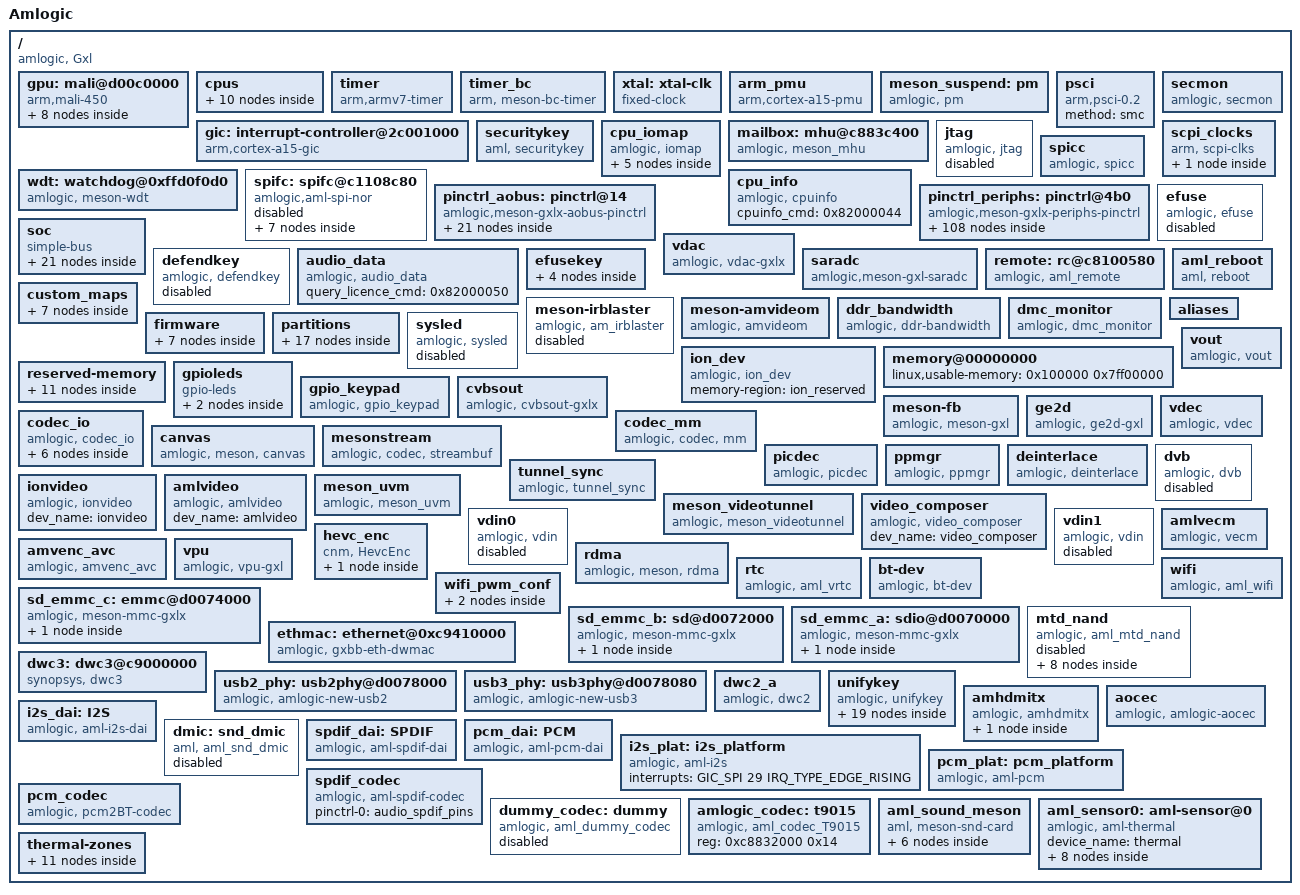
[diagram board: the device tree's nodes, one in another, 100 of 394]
/dts-v1/;

/* dt-bindings from khadas/linux khadas-vims-4.9.y (bd9460728746cc080acbaa084e53460437f43211), include/ */
#include <dt-bindings/clock/amlogic,gxl-clkc.h>
#include <dt-bindings/gpio/gpio.h>
#include <dt-bindings/interrupt-controller/arm-gic.h>
#include <dt-bindings/interrupt-controller/irq.h>
#include <dt-bindings/input/linux-event-codes.h>
#include <dt-bindings/thermal/thermal.h>

/ {
	model = "Amlogic";
	amlogic-dt-id = "gxlx2_p291_2g";
	compatible = "amlogic, Gxl";
	interrupt-parent = <&gic>;
	#address-cells = <1>;
	#size-cells = <1>;

	gpu: mali@d00c0000 {
		#cooling-cells = <2>;
		compatible = "arm,mali-450";
		interrupt-parent = <&gic>;
		reg = <0xd00c0000 0x40000 0xc1104440 0x1000 0xc8100000 0x1000 0xc883c000 0x1000 0xc1104440 0x1000>;
		interrupts = <GIC_SPI 160 IRQ_TYPE_LEVEL_HIGH>,
		             <GIC_SPI 161 IRQ_TYPE_LEVEL_HIGH>,
		             <GIC_SPI 162 IRQ_TYPE_LEVEL_HIGH>,
		             <GIC_SPI 163 IRQ_TYPE_LEVEL_HIGH>,
		             <GIC_SPI 164 IRQ_TYPE_LEVEL_HIGH>,
		             <GIC_SPI 165 IRQ_TYPE_LEVEL_HIGH>,
		             <GIC_SPI 166 IRQ_TYPE_LEVEL_HIGH>,
		             <GIC_SPI 167 IRQ_TYPE_LEVEL_HIGH>;
		interrupt-names = "IRQGP", "IRQGPMMU", "IRQPP", "IRQPMU", "IRQPP0", "IRQPPMMU0", "IRQPP1", "IRQPPMMU1";
		pmu_domain_config = <0x01 0x02 0x04 0x00 0x00 0x00 0x00 0x00 0x00 0x01 0x02 0x00>;
		pmu_switch_delay = <0xffff>;
		num_of_pp = <2>;
		def_clock = <0x03>;
		sc_mpp = <0x02>;
		tbl = <0x02 0x03 0x04 0x05 0x06 0x07>;
		clocks = <&clkc CLKID_GPU_MUX>, <&clkc CLKID_GP0_PLL>;
		clock-names = "gpu_mux", "gp0_pll";
		control_interval = <200>;
		phandle = <0x85>;

		clk125_cfg: clk125_cfg {
			clk_freq = <125000000>;
			clk_parent = "fclk_div4";
			clkp_freq = <500000000>;
			voltage = <1150>;
			keep_count = <5>;
			threshold = <30 120>;
			phandle = <0x02>;
		};

		clk250_cfg: clk250_cfg {
			clk_freq = <250000000>;
			clk_parent = "fclk_div4";
			clkp_freq = <500000000>;
			voltage = <1150>;
			keep_count = <5>;
			threshold = <80 170>;
			phandle = <0x87>;
		};

		clk285_cfg: clk285_cfg {
			clk_freq = <285000000>;
			clk_parent = "fclk_div7";
			clkp_freq = <285000000>;
			voltage = <1150>;
			keep_count = <5>;
			threshold = <100 190>;
			phandle = <0x03>;
		};

		clk400_cfg: clk400_cfg {
			clk_freq = <400000000>;
			clk_parent = "fclk_div5";
			clkp_freq = <400000000>;
			voltage = <1150>;
			keep_count = <5>;
			threshold = <152 207>;
			phandle = <0x04>;
		};

		clk500_cfg: clk500_cfg {
			clk_freq = <500000000>;
			clk_parent = "fclk_div4";
			clkp_freq = <500000000>;
			voltage = <1150>;
			keep_count = <5>;
			threshold = <180 220>;
			phandle = <0x05>;
		};

		clk666_cfg: clk666_cfg {
			clk_freq = <666000000>;
			clk_parent = "fclk_div3";
			clkp_freq = <666000000>;
			voltage = <1150>;
			keep_count = <5>;
			threshold = <210 236>;
			phandle = <0x06>;
		};

		clk750_cfg: clk750_cfg {
			clk_freq = <744000000>;
			clk_parent = "gp0_pll";
			clkp_freq = <744000000>;
			voltage = <1150>;
			keep_count = <5>;
			threshold = <230 255>;
			phandle = <0x07>;
		};

		clk800_cfg: clk800_cfg {
			clk_freq = <792000000>;
			clk_parent = "gp0_pll";
			clkp_freq = <792000000>;
			voltage = <1150>;
			keep_count = <5>;
			threshold = <230 255>;
			phandle = <0x88>;
		};
	};

	cpus: cpus {
		#address-cells = <1>;
		#size-cells = <0>;
		phandle = <0x89>;

		cpu-map {

			cluster0: cluster0 {
				phandle = <0x8a>;

				core0 {
					cpu = <&CPU0>;
				};

				core1 {
					cpu = <&CPU1>;
				};

				core2 {
					cpu = <&CPU2>;
				};

				core3 {
					cpu = <&CPU3>;
				};
			};
		};

		CPU0: cpu@0 {
			device_type = "cpu";
			compatible = "arm,cortex-a53", "arm,armv8";
			reg = <0x00>;
			enable-method = "psci";
			clocks = <&scpi_dvfs 0>;
			clock-names = "cpu-cluster.0";
			phandle = <0x09>;
		};

		CPU1: cpu@1 {
			device_type = "cpu";
			compatible = "arm,cortex-a53", "arm,armv8";
			reg = <0x01>;
			enable-method = "psci";
			clocks = <&scpi_dvfs 0>;
			clock-names = "cpu-cluster.0";
			phandle = <0x0a>;
		};

		CPU2: cpu@2 {
			device_type = "cpu";
			compatible = "arm,cortex-a53", "arm,armv8";
			reg = <0x02>;
			enable-method = "psci";
			clocks = <&scpi_dvfs 0>;
			clock-names = "cpu-cluster.0";
			phandle = <0x0b>;
		};

		CPU3: cpu@3 {
			device_type = "cpu";
			compatible = "arm,cortex-a53", "arm,armv8";
			reg = <0x03>;
			enable-method = "psci";
			clocks = <&scpi_dvfs 0>;
			clock-names = "cpu-cluster.0";
			phandle = <0x0c>;
		};
	};

	timer {
		compatible = "arm,armv7-timer";
		interrupts = <GIC_PPI 13 (GIC_CPU_MASK_SIMPLE(8) | IRQ_TYPE_EDGE_RISING)>,
		             <GIC_PPI 14 (GIC_CPU_MASK_SIMPLE(8) | IRQ_TYPE_EDGE_RISING)>,
		             <GIC_PPI 11 (GIC_CPU_MASK_SIMPLE(8) | IRQ_TYPE_EDGE_RISING)>,
		             <GIC_PPI 10 (GIC_CPU_MASK_SIMPLE(8) | IRQ_TYPE_EDGE_RISING)>;
	};

	timer_bc {
		compatible = "arm, meson-bc-timer";
		reg = <0xc1109990 0x04 0xc1109994 0x04>;
		timer_name = "Meson TimerF";
		clockevent-rating = <300>;
		clockevent-shift = <20>;
		clockevent-features = <0x23>;
		interrupts = <GIC_SPI 60 IRQ_TYPE_EDGE_RISING>;
		bit_enable = <0x10>;
		bit_mode = <0x0c>;
		bit_resolution = <0>;
	};

	xtal: xtal-clk {
		compatible = "fixed-clock";
		clock-frequency = <24000000>;
		clock-output-names = "xtal";
		#clock-cells = <0>;
		phandle = <0x10>;
	};

	arm_pmu {
		compatible = "arm,cortex-a15-pmu";
		interrupts = <GIC_SPI 137 IRQ_TYPE_LEVEL_HIGH>,
		             <GIC_SPI 138 IRQ_TYPE_LEVEL_HIGH>,
		             <GIC_SPI 153 IRQ_TYPE_LEVEL_HIGH>,
		             <GIC_SPI 154 IRQ_TYPE_LEVEL_HIGH>;
	};

	meson_suspend: pm {
		compatible = "amlogic, pm";
		status = "okay";
		device_name = "aml_pm";
		debug_reg = <0xc81000a8>;
		exit_reg = <0xc810023c>;
		phandle = <0x8b>;
	};

	gic: interrupt-controller@2c001000 {
		compatible = "arm,cortex-a15-gic", "arm,cortex-a9-gic";
		#interrupt-cells = <3>;
		#address-cells = <0>;
		interrupt-controller;
		reg = <0xc4301000 0x1000 0xc4302000 0x100>;
		interrupts = <GIC_PPI 9 (GIC_CPU_MASK_SIMPLE(4) | IRQ_TYPE_LEVEL_HIGH)>;
		phandle = <0x01>;
	};

	psci {
		compatible = "arm,psci-0.2";
		method = "smc";
	};

	secmon {
		compatible = "amlogic, secmon";
		memory-region = <&secmon_reserved>;
		in_base_func = <0x82000020>;
		out_base_func = <0x82000021>;
		reserve_mem_size = <0x200000>;
	};

	securitykey {
		compatible = "aml, securitykey";
		storage_query = <0x82000060>;
		storage_read = <0x82000061>;
		storage_write = <0x82000062>;
		storage_tell = <0x82000063>;
		storage_verify = <0x82000064>;
		storage_status = <0x82000065>;
		storage_list = <0x82000067>;
		storage_remove = <0x82000068>;
		storage_in_func = <0x82000023>;
		storage_out_func = <0x82000024>;
		storage_block_func = <0x82000025>;
		storage_size_func = <0x82000027>;
		storage_set_enctype = <0x8200006a>;
		storage_get_enctype = <0x8200006b>;
		storage_version = <0x8200006c>;
	};

	cpu_iomap {
		compatible = "amlogic, iomap";
		#address-cells = <1>;
		#size-cells = <1>;
		ranges;

		io_cbus_base {
			reg = <0xc1100000 0x100000>;
		};

		io_apb_base {
			reg = <0xd0000000 0x200000>;
		};

		io_aobus_base {
			reg = <0xc8100000 0x100000>;
		};

		io_vapb_base {
			reg = <0xd0100000 0x100000>;
		};

		io_hiu_base {
			reg = <0xc883c000 0x2000>;
		};
	};

	mailbox: mhu@c883c400 {
		compatible = "amlogic, meson_mhu";
		reg = <0xc883c400 0x4c 0xc8013000 0x800>;
		interrupts = <GIC_SPI 209 IRQ_TYPE_EDGE_RISING>, <GIC_SPI 210 IRQ_TYPE_EDGE_RISING>;
		#mbox-cells = <1>;
		mbox-names = "cpu_to_scp_low", "cpu_to_scp_high";
		mboxes = <&mailbox 0>, <&mailbox 1>;
		phandle = <0x0f>;
	};

	scpi_clocks {
		compatible = "arm, scpi-clks";

		scpi_dvfs: scpi_clocks@0 {
			compatible = "arm, scpi-clk-indexed";
			#clock-cells = <1>;
			clock-indices = <0x00>;
			clock-output-names = "vcpu";
			phandle = <0x0d>;
		};
	};

	wdt: watchdog@0xffd0f0d0 {
		compatible = "amlogic, meson-wdt";
		status = "okay";
		default_timeout = <10>;
		reset_watchdog_method = <0x01>;
		reset_watchdog_time = <0x02>;
		shutdown_timeout = <10>;
		firmware_timeout = <6>;
		suspend_timeout = <6>;
		reg = <0xc11098d0 0x10>;
		clock-names = "xtal";
		clocks = <&xtal>;
		phandle = <0x8c>;
	};

	jtag {
		compatible = "amlogic, jtag";
		status = "disabled";
		select = "disable";
		pinctrl-names = "jtag_apao_pins", "jtag_apee_pins";
		pinctrl-0 = <&jtag_a_pins>;
		pinctrl-1 = <&jtag_b_pins>;
	};

	spicc {
		compatible = "amlogic, spicc";
		status = "okay";
		reg = <0xc1108d80 0x3c>;
		clocks = <&clkc CLKID_SPICC>;
		clock-names = "spicc_clk";
		interrupts = <GIC_SPI 81 IRQ_TYPE_EDGE_RISING>;
		device_id = <0x00>;
		enhance = <0x01>;
	};

	spifc: spifc@c1108c80 {
		compatible = "amlogic,aml-spi-nor";
		status = "disabled";
		reg = <0xc1108c80 0x80>;
		pinctrl-names = "default";
		pinctrl-0 = <&spifc_all_pins>;
		clock-names = "core";
		clocks = <&clkc CLKID_CLK81>;
		phandle = <0x8d>;

		spi-nor@0 {
			cs_gpios = <&gpio 44 GPIO_ACTIVE_HIGH>;
			spifc-frequency = <16000000>;
			read-capability = <0x01>;
			spifc-io-width = <0x01>;
			spinor_partition = <&spinor_partitions>;

			spinor_partitions: spinor_partitions {
				phandle = <0x15>;

				bootloader {
					offset = <0x00 0x00>;
					size = <0x00 0x100000>;
				};

				env {
					offset = <0x00 0x00>;
					size = <0x00 0x40000>;
				};

				dtb {
					offset = <0x00 0x00>;
					size = <0x00 0x40000>;
				};

				boot {
					offset = <0x00 0x00>;
					size = <0x00 0x800000>;
				};

				user {
					offset = <0x00 0x00>;
					size = <0x00 0x680000>;
				};
			};
		};
	};

	cpu_info {
		compatible = "amlogic, cpuinfo";
		cpuinfo_cmd = <0x82000044>;
		status = "okay";
	};

	pinctrl_aobus: pinctrl@14 {
		compatible = "amlogic,meson-gxlx-aobus-pinctrl";
		#address-cells = <1>;
		#size-cells = <1>;
		ranges;
		phandle = <0x8e>;

		gpio_ao: bank@14 {
			reg = <0xc8100014 0x08>, <0xc810002c 0x04>, <0xc8100024 0x08>;
			reg-names = "mux", "pull", "gpio";
			gpio-controller;
			#gpio-cells = <2>;
			phandle = <0x3c>;
		};

		remote_pins: remote_pin {
			phandle = <0x20>;

			mux {
				groups = "remote_input";
				function = "remote";
			};
		};

		sd_to_ao_uart_clr_pins: sd_to_ao_uart_clr_pins {
			phandle = <0x4c>;

			mux {
				groups = "GPIOAO_0", "GPIOAO_1";
				function = "gpio_aobus";
			};
		};

		sd_to_ao_uart_pins: sd_to_ao_uart_pins {
			phandle = <0x4e>;

			mux {
				groups = "uart_tx_ao_a_0", "uart_rx_ao_a_0";
				function = "uart_ao";
				bias-pull-up;
				input-enable;
			};
		};

		ao_uart_pins: ao_uart {
			phandle = <0x8f>;

			mux {
				groups = "uart_tx_ao_a_0", "uart_rx_ao_a_0";
				function = "uart_ao";
			};
		};

		ao_b_uart_pins: ao_b_uart {
			phandle = <0x1a>;

			mux {
				groups = "uart_tx_ao_b_0", "uart_rx_ao_b_0";
				function = "uart_ao_b";
			};
		};

		ao_i2c_master: ao_i2c {
			phandle = <0x90>;

			mux {
				groups = "i2c_sda_ao", "i2c_sck_ao";
				function = "i2c_ao";
			};
		};

		hdmitx_aocec: hdmitx_aocec {
			phandle = <0x6f>;

			mux {
				groups = "ao_cec";
				function = "ao_cec";
			};
		};

		hdmitx_eecec: hdmitx_eecec {
			phandle = <0x91>;

			mux {
				groups = "ee_cec";
				function = "ee_cec";
			};
		};

		irblaster_pins: irblaster_pin {
			phandle = <0x22>;

			mux {
				groups = "ir_out_ao7";
				function = "ir_out";
			};
		};

		irblaster_pins1: irblaster_pin1 {
			phandle = <0x92>;

			mux {
				groups = "ir_out_ao9";
				function = "ir_out";
			};
		};
	};

	pinctrl_periphs: pinctrl@4b0 {
		compatible = "amlogic,meson-gxlx-periphs-pinctrl";
		#address-cells = <1>;
		#size-cells = <1>;
		ranges;
		phandle = <0x93>;

		gpio: bank@4b0 {
			reg = <0xc88344b0 0x28>,
			      <0xc88344e8 0x14>,
			      <0xc8834520 0x14>,
			      <0xc8834430 0x40>;
			reg-names = "mux", "pull", "pull-enable", "gpio";
			gpio-controller;
			#gpio-cells = <2>;
			phandle = <0x14>;
		};

		external_eth_pins: external_eth_pins {
			phandle = <0x56>;

			mux {
				groups = "eth_mdio", "eth_mdc", "eth_clk_rx_clk", "eth_rx_dv", "eth_rxd0", "eth_rxd1", "eth_rxd2", "eth_rxd3", "eth_rgmii_tx_clk", "eth_tx_en", "eth_txd0", "eth_txd1", "eth_txd2", "eth_txd3";
				function = "eth";
			};
		};

		jtag_a_pins: jtag_a_pin {
			phandle = <0x11>;

			mux {
				groups = "GPIOH_6", "GPIOH_7", "GPIOH_8", "GPIOH_9";
				function = "gpio_periphs";
			};
		};

		jtag_b_pins: jtag_b_pin {
			phandle = <0x12>;

			mux {
				groups = "CARD_0", "CARD_1", "CARD_2", "CARD_3";
				function = "gpio_periphs";
			};
		};

		a_uart_pins: a_uart {
			phandle = <0x16>;

			mux {
				groups = "uart_tx_a", "uart_rx_a", "uart_rts_a";
				function = "uart_a";
			};

			mux1 {
				groups = "uart_cts_a";
				function = "uart_a";
				bias-pull-down;
			};
		};

		b_uart_pins: b_uart {
			phandle = <0x17>;

			mux {
				groups = "uart_tx_b", "uart_rx_b", "uart_cts_b", "uart_rts_b";
				function = "uart_b";
			};
		};

		c_uart_pins: c_uart {
			phandle = <0x18>;

			mux {
				groups = "uart_tx_c", "uart_rx_c", "uart_cts_c", "uart_rts_c";
				function = "uart_c";
			};
		};

		pwm_b_pins: pwm_b_pins {
			phandle = <0x19>;

			mux {
				groups = "pwm_b";
				function = "pwm_b";
			};
		};

		wifi_32k_pins: wifi_32k_pins {
			phandle = <0x44>;

			mux {
				groups = "pwm_e";
				function = "pwm_e";
			};
		};

		ao_to_sd_uart_clr_pins: ao_to_sd_uart_clr_pins {
			phandle = <0x94>;

			mux {
				groups = "sdcard_d2", "sdcard_d3";
				function = "sdcard";
				input-enable;
				bias-pull-up;
			};
		};

		sd_1bit_pins: sd_1bit_pins {
			phandle = <0x4b>;

			mux {
				groups = "sdcard_d0", "sdcard_cmd", "sdcard_clk";
				function = "sdcard";
				input-enable;
				bias-pull-up;
			};
		};

		ao_to_sd_uart_pins: ao_to_sd_uart_pins {
			phandle = <0x4d>;

			mux {
				groups = "uart_tx_ao_a_card4", "uart_rx_ao_a_card5";
				function = "uart_ao_a_card";
				bias-pull-up;
				input-enable;
			};
		};

		emmc_clk_cmd_pins: emmc_clk_cmd_pins {
			phandle = <0x46>;

			mux {
				groups = "emmc_cmd", "emmc_clk";
				function = "emmc";
				input-enable;
				bias-pull-up;
			};
		};

		emmc_conf_pull_up: emmc_conf_pull_up {
			phandle = <0x47>;

			mux {
				groups = "emmc_nand_d07", "emmc_clk", "emmc_cmd";
				function = "emmc";
				input-enable;
				bias-pull-up;
			};
		};

		emmc_conf_pull_done: emmc_conf_pull_done {
			phandle = <0x48>;

			mux {
				groups = "emmc_ds";
				function = "emmc";
				input-enable;
				bias-pull-down;
			};
		};

		sd_clk_cmd_pins: sd_clk_cmd_pins {
			phandle = <0x4a>;

			mux {
				groups = "sdcard_cmd", "sdcard_clk";
				function = "sdcard";
				input-enable;
				bias-pull-up;
			};
		};

		sd_all_pins: sd_all_pins {
			phandle = <0x49>;

			mux {
				groups = "sdcard_d0", "sdcard_d1", "sdcard_d2", "sdcard_d3", "sdcard_cmd", "sdcard_clk";
				function = "sdcard";
				input-enable;
				bias-pull-up;
			};
		};

		sdio_clk_cmd_pins: sdio_clk_cmd_pins {
			phandle = <0x4f>;

			mux {
				groups = "sdio_clk", "sdio_cmd";
				function = "sdio";
				input-enable;
				bias-pull-up;
			};
		};

		sdio_all_pins: sdio_all_pins {
			phandle = <0x50>;

			mux {
				groups = "sdio_d0", "sdio_d1", "sdio_d2", "sdio_d3", "sdio_clk", "sdio_cmd";
				function = "sdio";
				input-enable;
				bias-pull-up;
			};
		};

		sd_iso7816_pins: sd_iso7816_pins {
			phandle = <0x95>;

			mux {
				groups = "iso7816_clk_dv", "iso7816_data_dv";
				function = "iso7816";
				input-enable;
				bias-pull-down;
			};
		};

		nand_pulldown: nand_pulldown {
			phandle = <0x96>;

			mux {
				groups = "emmc_nand_d07", "emmc_ds";
				function = "emmc";
				bias-pull-down;
			};
		};

		nand_pullup: nand_pullup {
			phandle = <0x97>;

			mux {
				groups = "emmc_clk", "emmc_cmd";
				function = "emmc";
				bias-pull-up;
			};
		};

		all_nand_pins: all_nand_pins {
			phandle = <0x51>;

			mux {
				groups = "emmc_nand_d07", "nand_ce0", "nand_ce1", "nand_rb0", "nand_ale", "nand_cle", "nand_wen_clk", "nand_ren_wr", "nand_dqs";
				function = "nand";
				input-enable;
			};
		};

		nand_cs_pins: nand_cs {
			phandle = <0x52>;

			mux {
				groups = "nand_ce0", "nand_ce1";
				function = "nand";
			};
		};

		hdmitx_hpd: hdmitx_hpd {
			phandle = <0x6d>;

			mux {
				groups = "hdmi_hpd";
				function = "hdmi_hpd";
			};
		};

		hdmitx_ddc: hdmitx_ddc {
			phandle = <0x6e>;

			mux {
				groups = "hdmi_sda", "hdmi_scl";
				function = "hdmi_ddc";
			};
		};

		a_i2c_master: a_i2c {
			phandle = <0x98>;

			mux {
				groups = "i2c_sda_a", "i2c_scl_a";
				function = "i2c_a";
			};
		};

		b_i2c_master: b_i2c {
			phandle = <0x99>;

			mux {
				groups = "i2c_sda_b", "i2c_scl_b";
				function = "i2c_b";
			};
		};

		c_i2c_master: c_i2c {
			phandle = <0x9a>;

			mux {
				groups = "i2c_sda_c_dv28", "i2c_scl_c_dv29";
				function = "i2c_c";
			};
		};

		c_i2c_master_pin1: c_i2c_pin1 {
			phandle = <0x9b>;

			mux {
				groups = "i2c_sda_c_dv18", "i2c_scl_c_dv19";
				function = "i2c_c";
			};
		};

		d_i2c_master: d_i2c {
			phandle = <0x9c>;

			mux {
				groups = "i2c_sda_d", "i2c_scl_d";
				function = "i2c_d";
			};
		};

		spicc_pulldown_z11z12z13: spicc_pulldown_z11z12z13 {
			phandle = <0x9d>;

			mux {
				groups = "spi_sclk_0", "spi_miso_0", "spi_mosi_0";
				function = "spi";
			};
		};

		spicc_pullup_z11z12z13: spicc_pullup_z11z12z13 {
			phandle = <0x9e>;

			mux {
				groups = "spi_sclk_0", "spi_miso_0", "spi_mosi_0";
				function = "spi";
			};
		};

		spicc_pulldown_x8x9x11: spicc_pulldown_x8x9x11 {
			phandle = <0x9f>;

			mux {
				groups = "spi_sclk_1", "spi_miso_1", "spi_mosi_1";
				function = "spi";
				bias-pull-down;
			};
		};

		spicc_pullup_x8x9x11: spicc_pullup_x8x9x11 {
			phandle = <0xa0>;

			mux {
				groups = "spi_sclk_1", "spi_miso_1", "spi_mosi_1";
				function = "spi";
				bias-pull-up;
			};
		};

		spicc_pins: spicc {
			phandle = <0xa1>;

			mux {
				groups = "spi_sclk_1", "spi_miso_1", "spi_mosi_1", "spi_ss0_1";
				function = "spi";
			};
		};

		spifc_all_pins: spifc_all_pins {
			phandle = <0x13>;

			mux {
				groups = "nor_d", "nor_q", "nor_c";
				function = "nor";
				input-enable;
				bias-pull-down;
			};
		};

		audio_i2s_pins: audio_i2s {
			phandle = <0x72>;

			mux {
				groups = "i2s_am_clk", "i2s_ao_clk_out", "i2s_lr_clk_out", "i2sout_ch01";
				function = "i2s";
			};
		};

		audio_spdif_pins: audio_spdif {
			phandle = <0x71>;

			mux {
				groups = "spdif_out";
				function = "spdif_out";
			};
		};

		audio_spdif_in_pins: audio_spdif_in {
			phandle = <0xa2>;

			mux {
				groups = "spdif_in_z14";
				function = "spdif_in";
			};
		};

		audio_spdif_in_1_pins: audio_spdif_in_1 {
			phandle = <0xa3>;

			mux {
				groups = "spdif_in_h4";
				function = "spdif_in";
			};
		};

		audio_pcm_pins: audio_pcm {
			phandle = <0xa4>;

			mux {
				groups = "pcm_out_a", "pcm_in_a", "pcm_fs_a", "pcm_clk_a";
				function = "pcm_a";
			};
		};

		aml_dmic_pins: audio_dmic {
			phandle = <0x70>;

			mux {
				groups = "dmic_in_dv24", "dmic_clk_dv25";
				function = "dmic";
			};
		};

		dvb_p_ts0_pins: dvb_p_ts0_pins {
			phandle = <0xa5>;

			tsin_a {
				groups = "tsin_sop_a_dv9", "tsin_d_valid_a_dv10", "tsin_d0_a_dv0", "tsin_d1_7_a_dv1_7", "tsin_clk_a_dv8";
				function = "tsin_a";
			};
		};

		dvb_s_ts0_pins: dvb_s_ts0_pins {
			phandle = <0xa6>;

			tsin_a {
				groups = "tsin_sop_a_dv9", "tsin_d_valid_a_dv10", "tsin_clk_a_dv8", "tsin_d0_a_dv0";
				function = "tsin_a";
			};
		};

		lcd_ttl_rgb_6bit_on_pins: lcd_ttl_rgb_6bit_on {
			phandle = <0xa7>;

			mux {
				groups = "lcd_r2_7", "lcd_g2_7", "lcd_b2_7";
				function = "lcd_ttl";
			};
		};

		lcd_ttl_rgb_6bit_off_pins: lcd_ttl_rgb_6bit_off {
			phandle = <0xa8>;

			mux {
				groups = "GPIODV_2", "GPIODV_3", "GPIODV_4", "GPIODV_5", "GPIODV_6", "GPIODV_7", "GPIODV_10", "GPIODV_11", "GPIODV_12", "GPIODV_13", "GPIODV_14", "GPIODV_15", "GPIODV_18", "GPIODV_19", "GPIODV_20", "GPIODV_21", "GPIODV_22", "GPIODV_23";
				function = "gpio_periphs";
				input-enable;
			};
		};

		lcd_ttl_rgb_8bit_on_pins: lcd_ttl_rgb_8bit_on {
			phandle = <0xa9>;

			mux {
				groups = "lcd_r0_1", "lcd_r2_7", "lcd_g0_1", "lcd_g2_7", "lcd_b0_1", "lcd_b2_7";
				function = "lcd_ttl";
			};
		};

		lcd_ttl_rgb_8bit_off_pins: lcd_ttl_rgb_8bit_off {
			phandle = <0xaa>;

			mux {
				groups = "GPIODV_0", "GPIODV_1", "GPIODV_2", "GPIODV_3", "GPIODV_4", "GPIODV_5", "GPIODV_6", "GPIODV_7", "GPIODV_8", "GPIODV_9", "GPIODV_10", "GPIODV_11", "GPIODV_12", "GPIODV_13", "GPIODV_14", "GPIODV_15", "GPIODV_16", "GPIODV_17", "GPIODV_18", "GPIODV_19", "GPIODV_20", "GPIODV_21", "GPIODV_22", "GPIODV_23";
				function = "gpio_periphs";
				input-enable;
			};
		};

		lcd_ttl_de_on_pins: lcd_ttl_de_on_pin {
			phandle = <0xab>;

			mux {
				groups = "tcon_cph", "tcon_oeh";
				function = "lcd_ttl";
			};
		};

		lcd_ttl_hvsync_on_pins: lcd_ttl_hvsync_on_pin {
			phandle = <0xac>;

			mux {
				groups = "tcon_cph", "tcon_stv1", "tcon_sth1";
				function = "lcd_ttl";
			};
		};

		lcd_ttl_de_hvsync_on_pins: lcd_ttl_de_hvsync_on_pin {
			phandle = <0xad>;

			mux {
				groups = "tcon_cph", "tcon_oeh", "tcon_stv1", "tcon_sth1";
				function = "lcd_ttl";
			};
		};

		lcd_ttl_de_hvsync_off_pins: lcd_ttl_de_hvsync_off_pin {
			phandle = <0xae>;

			mux {
				groups = "GPIODV_26", "GPIODV_27", "GPIODV_24", "GPIODV_25";
				function = "gpio_periphs";
				input-enable;
			};
		};

		spdifout_a_mute: spdifout_a_mute {
			phandle = <0xaf>;

			mux {
				groups = "GPIOH_4";
				function = "gpio_periphs";
			};
		};
	};

	soc {
		compatible = "simple-bus";
		#address-cells = <1>;
		#size-cells = <1>;
		ranges;

		cbus: cbus@c1100000 {
			compatible = "simple-bus";
			reg = <0xc1100000 0x100000>;
			#address-cells = <1>;
			#size-cells = <1>;
			ranges = <0x00 0xc1100000 0x100000>;
			phandle = <0xb0>;

			meson_clk_msr {
				compatible = "amlogic,gxlx-measure";
				reg = <0x875c 0x04 0x8764 0x04>;
			};

			uart_A: serial@84c0 {
				compatible = "amlogic, meson-uart";
				reg = <0x84c0 0x18>;
				interrupts = <GIC_SPI 26 IRQ_TYPE_EDGE_RISING>;
				status = "okay";
				clocks = <&clkc CLKID_UART0>;
				clock-names = "clk_uart";
				fifosize = <128>;
				pinctrl-names = "default";
				pinctrl-0 = <&a_uart_pins>;
				phandle = <0xb1>;
			};

			uart_B: serial@84dc {
				compatible = "amlogic, meson-uart";
				reg = <0x84dc 0x18>;
				interrupts = <GIC_SPI 75 IRQ_TYPE_EDGE_RISING>;
				status = "disabled";
				clocks = <&clkc CLKID_UART1>;
				clock-names = "clk_uart";
				fifosize = <64>;
				pinctrl-names = "default";
				pinctrl-0 = <&b_uart_pins>;
				phandle = <0xb2>;
			};

			uart_C: serial@8700 {
				compatible = "amlogic, meson-uart";
				reg = <0x8700 0x18>;
				interrupts = <GIC_SPI 93 IRQ_TYPE_EDGE_RISING>;
				status = "disabled";
				clocks = <&clkc CLKID_UART2>;
				clock-names = "clk_uart";
				fifosize = <64>;
				pinctrl-names = "default";
				pinctrl-0 = <&c_uart_pins>;
				phandle = <0xb3>;
			};

			pwm_ab: pwm@8550 {
				compatible = "amlogic,gx-ee-pwm";
				reg = <0x8550 0x1c>;
				#pwm-cells = <3>;
				clocks = <&xtal>, <&xtal>, <&xtal>, <&xtal>;
				clock-names = "clkin0", "clkin1", "clkin2", "clkin3";
				status = "okay";
				pinctrl-names = "pwm_b_pins";
				pinctrl-0 = <&pwm_b_pins>;
				phandle = <0xb4>;
			};

			pwm_cd: pwm@8640 {
				compatible = "amlogic,gx-ee-pwm";
				reg = <0x8640 0x1c>;
				#pwm-cells = <3>;
				clocks = <&xtal>, <&xtal>, <&xtal>, <&xtal>;
				clock-names = "clkin0", "clkin1", "clkin2", "clkin3";
				status = "okay";
				phandle = <0xb5>;
			};

			pwm_ef: pwm@86c0 {
				compatible = "amlogic,gx-ee-pwm";
				reg = <0x86c0 0x1c>;
				#pwm-cells = <3>;
				clocks = <&xtal>, <&xtal>, <&xtal>, <&xtal>;
				clock-names = "clkin0", "clkin1", "clkin2", "clkin3";
				status = "okay";
				phandle = <0x45>;
			};

			i2c0: i2c@8500 {
				compatible = "amlogic,meson-gx-i2c";
				status = "disabled";
				reg = <0x8500 0x20>;
				interrupts = <GIC_SPI 21 IRQ_TYPE_EDGE_RISING>,
				             <GIC_SPI 47 IRQ_TYPE_EDGE_RISING>;
				#address-cells = <1>;
				#size-cells = <0>;
				clocks = <&clkc CLKID_I2C>;
				clock-names = "clk_i2c";
				phandle = <0xb6>;
			};

			i2c1: i2c@87c0 {
				compatible = "amlogic,meson-gx-i2c";
				status = "disabled";
				reg = <0x87c0 0x20>;
				interrupts = <GIC_SPI 214 IRQ_TYPE_EDGE_RISING>,
				             <GIC_SPI 48 IRQ_TYPE_EDGE_RISING>;
				#address-cells = <1>;
				#size-cells = <0>;
				clocks = <&clkc CLKID_I2C>;
				clock-names = "clk_i2c";
				phandle = <0xb7>;
			};

			i2c2: i2c@87e0 {
				compatible = "amlogic,meson-gx-i2c";
				status = "disabled";
				reg = <0x87e0 0x20>;
				interrupts = <GIC_SPI 215 IRQ_TYPE_EDGE_RISING>,
				             <GIC_SPI 49 IRQ_TYPE_EDGE_RISING>;
				#address-cells = <1>;
				#size-cells = <0>;
				clocks = <&clkc CLKID_I2C>;
				clock-names = "clk_i2c";
				phandle = <0xb8>;
			};

			i2c3: i2c@8d20 {
				compatible = "amlogic,meson-gx-i2c";
				status = "disabled";
				reg = <0x8d20 0x20>;
				interrupts = <GIC_SPI 39 IRQ_TYPE_EDGE_RISING>,
				             <GIC_SPI 50 IRQ_TYPE_EDGE_RISING>;
				#address-cells = <1>;
				#size-cells = <0>;
				clocks = <&clkc CLKID_I2C>;
				clock-names = "clk_i2c";
				phandle = <0xb9>;
			};
		};

		aobus: aobus@c8100000 {
			compatible = "simple-bus";
			reg = <0xc8100000 0x100000>;
			#address-cells = <1>;
			#size-cells = <1>;
			ranges = <0x00 0xc8100000 0x100000>;
			phandle = <0xba>;

			cpu_version {
				reg = <0x220 0x04>;
			};

			uart_AO: serial@4c0 {
				compatible = "amlogic, meson-uart";
				reg = <0x4c0 0x18>;
				interrupts = <GIC_SPI 193 IRQ_TYPE_EDGE_RISING>;
				status = "okay";
				clocks = <&xtal>;
				clock-names = "clk_uart";
				xtal_tick_en = <0x01>;
				fifosize = <64>;
				pinctrl-names = "default";
				support-sysrq = <0x00>;
				phandle = <0xbb>;
			};

			uart_AO_B: serial@4e0 {
				compatible = "amlogic, meson-uart";
				reg = <0x4e0 0x18>;
				interrupts = <GIC_SPI 197 IRQ_TYPE_EDGE_RISING>;
				status = "disable";
				clocks = <&xtal>;
				clock-names = "clk_uart";
				fifosize = <64>;
				pinctrl-names = "default";
				pinctrl-0 = <&ao_b_uart_pins>;
				phandle = <0xbc>;
			};

			pwm_aoab: pwm@550 {
				compatible = "amlogic,gx-ao-pwm";
				reg = <0x550 0x1c>;
				#pwm-cells = <3>;
				clocks = <&xtal>, <&xtal>, <&xtal>, <&xtal>;
				clock-names = "clkin0", "clkin1", "clkin2", "clkin3";
				status = "disabled";
				phandle = <0xbd>;
			};
		};

		periphs: periphs@c8834000 {
			compatible = "simple-bus";
			reg = <0xc8834000 0x2000>;
			#address-cells = <1>;
			#size-cells = <1>;
			ranges = <0x00 0xc8834000 0x2000>;
			phandle = <0xbe>;

			rng {
				compatible = "amlogic,meson-rng";
				reg = <0x00 0x04>;
				quality = [03 e8];
			};
		};

		hiubus: hiubus@c883c000 {
			compatible = "simple-bus";
			reg = <0xc883c000 0x2000>;
			#address-cells = <1>;
			#size-cells = <1>;
			ranges = <0x00 0xc883c000 0x2000>;
			phandle = <0xbf>;

			clkc: clock-controller@0 {
				compatible = "amlogic,gxl-clkc";
				#clock-cells = <1>;
				#reset-cells = <1>;
				reg = <0x00 0x3db>;
				phandle = <0x08>;
			};
		};
	};

	vdac {
		compatible = "amlogic, vdac-gxlx";
		status = "okay";
	};

	defendkey: defendkey {
		compatible = "amlogic, defendkey";
		reg = <0xc8834500 0x04>;
		mem_size = <0x00 0x100000>;
		status = "disabled";
		phandle = <0xc0>;
	};

	audio_data: audio_data {
		compatible = "amlogic, audio_data";
		query_licence_cmd = <0x82000050>;
		status = "okay";
		phandle = <0xc1>;
	};

	saradc: saradc {
		compatible = "amlogic,meson-gxl-saradc";
		status = "okay";
		#io-channel-cells = <1>;
		clocks = <&xtal>, <&clkc CLKID_SARADC>, <&clkc CLKID_SARADC_COMP>;
		clock-names = "xtal", "clk81_gate", "saradc_clk";
		interrupts = <GIC_SPI 73 IRQ_TYPE_EDGE_RISING>;
		reg = <0x00 0xc1108680 0x00 0x38>;
		phandle = <0xc2>;
	};

	efuse: efuse {
		compatible = "amlogic, efuse";
		read_cmd = <0x82000030>;
		write_cmd = <0x82000031>;
		get_max_cmd = <0x82000033>;
		key = <&efusekey>;
		clocks = <&clkc CLKID_EFUSE>;
		clock-names = "efuse_clk";
		status = "disabled";
		phandle = <0xc3>;
	};

	efusekey: efusekey {
		keynum = <4>;
		key0 = <&key_0>;
		key1 = <&key_1>;
		key2 = <&key_2>;
		key3 = <&key_3>;
		phandle = <0x1b>;

		key_0: key_0 {
			keyname = "mac";
			offset = <0x00>;
			size = <0x06>;
			phandle = <0x1c>;
		};

		key_1: key_1 {
			keyname = "mac_bt";
			offset = <0x06>;
			size = <0x06>;
			phandle = <0x1d>;
		};

		key_2: key_2 {
			keyname = "mac_wifi";
			offset = <0x0c>;
			size = <0x06>;
			phandle = <0x1e>;
		};

		key_3: key_3 {
			keyname = "usid";
			offset = <0x12>;
			size = <0x10>;
			phandle = <0x1f>;
		};
	};

	remote: rc@c8100580 {
		compatible = "amlogic, aml_remote";
		dev_name = "meson-remote";
		reg = <0xc8100580 0x44 0xc8100480 0x20>;
		status = "okay";
		protocol = <0x01>;
		interrupts = <GIC_SPI 196 IRQ_TYPE_EDGE_RISING>;
		pinctrl-names = "default";
		pinctrl-0 = <&remote_pins>;
		map = <&custom_maps>;
		max_frame_time = <200>;
		phandle = <0xc4>;
	};

	meson-irblaster {
		compatible = "amlogic, am_irblaster";
		dev_name = "meson-irblaster";
		status = "disabled";
		pinctrl-names = "default";
		pinctrl-0 = <&irblaster_pins>;
	};

	custom_maps: custom_maps {
		mapnum = <7>;
		map0 = <&map_0>;
		map1 = <&map_1>;
		map2 = <&map_2>;
		map3 = <&map_3>;
		map4 = <&map_4>;
		map5 = <&map_5>;
		map6 = <&map_6>;
		phandle = <0x21>;

		map_0: map_0 {
			mapname = "amlogic-remote-1";
			customcode = <0xfeaa>;
			release_delay = <65>;
			size = <0x1c>;
			keymap = <0x400074 0x4b0192 0x4f0193 0x4300c1 0xf00c2 0x180073 0x100072 0x110066 0x19009e 0x160067 0x1a006c 0x510069 0x50006a 0x13001c 0x4c008b 0xaf 0x4e018e 0xd018f 0xc0004 0x4a0005 0x90006 0x80007 0x460190 0x50191 0x4000a 0x1000b 0x410071 0x42000e>;
			fn_key_scancode = <0x00>;
			cursor_left_scancode = <0x51>;
			cursor_right_scancode = <0x50>;
			cursor_up_scancode = <0x16>;
			cursor_down_scancode = <0x1a>;
			cursor_ok_scancode = <0x13>;
			phandle = <0x23>;
		};

		map_1: map_1 {
			mapname = "amlogic-remote-2";
			customcode = <0xfe01>;
			release_delay = <80>;
			size = <0x1c>;
			keymap = <0x400074 0x4b0192 0x4f0193 0x430057 0xf0058 0x180073 0x100072 0x110066 0x19009e 0x160067 0x1a006c 0x510069 0x50006a 0x13001c 0x4c008b 0xaf 0x4e0002 0xd0003 0xc0004 0x4a0005 0x90006 0x80007 0x460008 0x50009 0x4000a 0x1000b 0x410071 0x42000e>;
			fn_key_scancode = <0x00>;
			cursor_left_scancode = <0x51>;
			cursor_right_scancode = <0x50>;
			cursor_up_scancode = <0x16>;
			cursor_down_scancode = <0x1a>;
			cursor_ok_scancode = <0x13>;
			phandle = <0x24>;
		};

		map_2: map_2 {
			mapname = "amlogic-remote-3";
			customcode = <0x7f80>;
			release_delay = <80>;
			size = <0x0c>;
			keymap = <0x810074 0x83008b 0x730066 0x380067 0x40006c 0x370069 0x39006a 0x13001c 0x27009e 0x870073 0x890072 0x4800af>;
			fn_key_scancode = <0x48>;
			cursor_left_scancode = <0x37>;
			cursor_right_scancode = <0x39>;
			cursor_up_scancode = <0x38>;
			cursor_down_scancode = <0x40>;
			cursor_ok_scancode = <0x13>;
			phandle = <0x25>;
		};

		map_3: map_3 {
			mapname = "amlogic-remote-4";
			customcode = <0xfb04>;
			release_delay = <80>;
			size = <0x22>;
			keymap = <0x80074 0x4a008b 0x2f00af 0xa4003f 0xb20057 0x450067 0x46006c 0x470069 0x48006a 0x44001c 0x1a009e 0x1b000e 0x2d0066 0x20073 0x30072 0x90071 0x192 0x10193 0x17004b 0x90004c 0x610002 0x620003 0x630004 0x640005 0x650006 0x660007 0x670008 0x680009 0x69000a 0x60000b 0xfb0040 0xeb0041 0xb30042 0xb40043>;
			fn_key_scancode = <0x2f>;
			cursor_left_scancode = <0x47>;
			cursor_right_scancode = <0x48>;
			cursor_up_scancode = <0x45>;
			cursor_down_scancode = <0x46>;
			cursor_ok_scancode = <0x44>;
			phandle = <0x26>;
		};

		map_4: map_4 {
			mapname = "amlogic-remote-5";
			customcode = <0xdf00>;
			release_delay = <80>;
			size = <0x1c>;
			keymap = <0x1c0074 0x4b0042 0x4f003c 0x1003d 0x5f003e 0x5d0073 0x5c0072 0x420066 0xa009e 0x1a0067 0x48006c 0x470069 0x7006a 0x6001c 0x18008b 0x540002 0x160003 0x150004 0x500005 0x120006 0x110007 0x4c0008 0xe0009 0xd000a 0x41003f 0xc000b 0x10000e 0x30184>;
			fn_key_scancode = <0x03>;
			cursor_left_scancode = <0x47>;
			cursor_right_scancode = <0x07>;
			cursor_up_scancode = <0x1a>;
			cursor_down_scancode = <0x48>;
			cursor_ok_scancode = <0x06>;
			phandle = <0x27>;
		};

		map_5: map_5 {
			mapname = "amlogic-remote-6";
			customcode = <0x212>;
			release_delay = <80>;
			size = <0x22>;
			keymap = <0x80074 0x4a008b 0x2f00af 0xa4003f 0xb20057 0x450067 0x46006c 0x470069 0x48006a 0x44001c 0x1a009e 0x1b000e 0x2d0066 0x20073 0x30072 0x90071 0x192 0x10193 0x17004b 0x90004c 0x610002 0x620003 0x630004 0x640005 0x650006 0x660007 0x670008 0x680009 0x69000a 0x60000b 0xfb0040 0xeb0041 0xb30042 0xb40043>;
			fn_key_scancode = <0x2f>;
			cursor_left_scancode = <0x47>;
			cursor_right_scancode = <0x48>;
			cursor_up_scancode = <0x45>;
			cursor_down_scancode = <0x46>;
			cursor_ok_scancode = <0x44>;
			phandle = <0x28>;
		};

		map_6: map_6 {
			mapname = "amlogic-remote-7";
			customcode = <0xff00>;
			release_delay = <80>;
			size = <0x1c>;
			keymap = <0x180074 0x30175 0x140072 0x100073 0x60066 0x40009e 0x4008b 0x460067 0x16006c 0x470069 0x15006a 0x55001c 0x540002 0x480003 0x70004 0x500005 0x120006 0x110007 0x4c0008 0xe0009 0xd000a 0xc000b 0x4b000e 0x140072 0x80071 0x100073 0x560043 0x570044>;
			phandle = <0x29>;
		};
	};

	meson-amvideom {
		compatible = "amlogic, amvideom";
		dev_name = "amvideom";
		status = "okay";
		interrupts = <GIC_SPI 3 IRQ_TYPE_EDGE_RISING>;
		interrupt-names = "vsync";
	};

	aml_reboot {
		compatible = "aml, reboot";
		sys_reset = <0x84000009>;
		sys_poweroff = <0x84000008>;
	};

	ddr_bandwidth {
		compatible = "amlogic, ddr-bandwidth";
		status = "okay";
		reg = <0xc8838000 0x100 0xc8837000 0x100>;
		sec_base = <0xda838400>;
		interrupts = <GIC_SPI 52 IRQ_TYPE_EDGE_RISING>;
		interrupt-names = "ddr_bandwidth";
	};

	dmc_monitor {
		compatible = "amlogic, dmc_monitor";
		status = "okay";
		reg_base = <0xda838400>;
		interrupts = <GIC_SPI 51 IRQ_TYPE_EDGE_RISING>;
	};

	firmware {

		android {
			compatible = "android,firmware";

			vbmeta {
				compatible = "android,vbmeta";
				parts = "vbmeta,boot,system,vendor";
				by_name_prefix = "/dev/block";
			};

			fstab {
				compatible = "android,fstab";

				system {
					compatible = "android,system";
					dev = "/dev/block/system";
					type = "ext4";
					mnt_flags = "ro,barrier=1,inode_readahead_blks=8";
					fsmgr_flags = "wait";
				};

				vendor {
					compatible = "android,vendor";
					dev = "/dev/block/vendor";
					type = "ext4";
					mnt_flags = "ro,barrier=1,inode_readahead_blks=8";
					fsmgr_flags = "wait";
				};

				odm {
					compatible = "android,odm";
					dev = "/dev/block/odm";
					type = "ext4";
					mnt_flags = "ro,barrier=1,inode_readahead_blks=8";
					fsmgr_flags = "wait";
				};

				product {
					compatible = "android,product";
					dev = "/dev/block/product";
					type = "ext4";
					mnt_flags = "ro,barrier=1,inode_readahead_blks=8";
					fsmgr_flags = "wait";
				};
			};
		};
	};

	partitions: partitions {
		parts = <17>;
		part-0 = <&logo>;
		part-1 = <&recovery>;
		part-2 = <&misc>;
		part-3 = <&dtbo>;
		part-4 = <&cri_data>;
		part-5 = <&param>;
		part-6 = <&boot>;
		part-7 = <&rsv>;
		part-8 = <&metadata>;
		part-9 = <&vbmeta>;
		part-10 = <&tee>;
		part-11 = <&vendor>;
		part-12 = <&odm>;
		part-13 = <&system>;
		part-14 = <&product>;
		part-15 = <&cache>;
		part-16 = <&data>;
		phandle = <0xc5>;

		logo: logo {
			pname = "logo";
			size = <0x00 0x800000>;
			mask = <0x01>;
			phandle = <0x2a>;
		};

		recovery: recovery {
			pname = "recovery";
			size = <0x00 0x1800000>;
			mask = <0x01>;
			phandle = <0x2b>;
		};

		misc: misc {
			pname = "misc";
			size = <0x00 0x800000>;
			mask = <0x01>;
			phandle = <0x2c>;
		};

		dtbo: dtbo {
			pname = "dtbo";
			size = <0x00 0x800000>;
			mask = <0x01>;
			phandle = <0x2d>;
		};

		cri_data: cri_data {
			pname = "cri_data";
			size = <0x00 0x800000>;
			mask = <0x02>;
			phandle = <0x2e>;
		};

		rsv: rsv {
			pname = "rsv";
			size = <0x00 0x1000000>;
			mask = <0x01>;
			phandle = <0x31>;
		};

		metadata: metadata {
			pname = "metadata";
			size = <0x00 0x1000000>;
			mask = <0x01>;
			phandle = <0x32>;
		};

		vbmeta: vbmeta {
			pname = "vbmeta";
			size = <0x00 0x200000>;
			mask = <0x01>;
			phandle = <0x33>;
		};

		param: param {
			pname = "param";
			size = <0x00 0x1000000>;
			mask = <0x02>;
			phandle = <0x2f>;
		};

		boot: boot {
			pname = "boot";
			size = <0x00 0x1000000>;
			mask = <0x01>;
			phandle = <0x30>;
		};

		tee: tee {
			pname = "tee";
			size = <0x00 0x2000000>;
			mask = <0x01>;
			phandle = <0x34>;
		};

		vendor: vendor {
			pname = "vendor";
			size = <0x00 0x14000000>;
			mask = <0x01>;
			phandle = <0x35>;
		};

		odm: odm {
			pname = "odm";
			size = <0x00 0x8000000>;
			mask = <0x01>;
			phandle = <0x36>;
		};

		system: system {
			pname = "system";
			size = <0x00 0x60000000>;
			mask = <0x01>;
			phandle = <0x37>;
		};

		product: product {
			pname = "product";
			size = <0x00 0x8000000>;
			mask = <0x01>;
			phandle = <0x38>;
		};

		cache: cache {
			pname = "cache";
			size = <0x00 0x46000000>;
			mask = <0x02>;
			phandle = <0x39>;
		};

		data: data {
			pname = "data";
			size = <0xffffffff 0xffffffff>;
			mask = <0x04>;
			phandle = <0x3a>;
		};
	};

	ion_dev {
		compatible = "amlogic, ion_dev";
		memory-region = <&ion_reserved>;
	};

	aliases {
		serial0 = "/soc/aobus@c8100000/serial@4c0";
		serial1 = "/soc/cbus@c1100000/serial@84c0";
		serial2 = "/soc/cbus@c1100000/serial@84dc";
		serial3 = "/soc/cbus@c1100000/serial@8700";
		serial4 = "/soc/aobus@c8100000/serial@4e0";
	};

	memory@00000000 {
		device_type = "memory";
		linux,usable-memory = <0x100000 0x7ff00000>;
	};

	reserved-memory {
		#address-cells = <1>;
		#size-cells = <1>;
		ranges;

		ramoops@0x07400000 {
			compatible = "ramoops";
			reg = <0x7400000 0x100000>;
			record-size = <0x8000>;
			console-size = <0x8000>;
			ftrace-size = <0x40000>;
		};

		secmon_reserved: linux,secmon {
			compatible = "shared-dma-pool";
			reusable;
			size = <0x400000>;
			alignment = <0x400000>;
			alloc-ranges = <0x10000000 0x400000>;
			phandle = <0x0e>;
		};

		secos_reserved: linux,secos {
			status = "disable";
			compatible = "amlogic, aml_secos_memory";
			reg = <0x5300000 0x2000000>;
			no-map;
			phandle = <0xc6>;
		};

		logo_reserved: linux,meson-fb {
			compatible = "shared-dma-pool";
			reusable;
			size = <0x800000>;
			alignment = <0x400000>;
			alloc-ranges = <0x7f800000 0x800000>;
			phandle = <0x3d>;
		};

		di_cma_reserved: linux,di_cma {
			compatible = "shared-dma-pool";
			reusable;
			size = <0x4400000>;
			alignment = <0x400000>;
			phandle = <0x42>;
		};

		ion_reserved: linux,ion-dev {
			compatible = "shared-dma-pool";
			reusable;
			size = <0x7c00000>;
			alignment = <0x400000>;
			alloc-ranges = <0x30000000 0x50000000>;
			phandle = <0x3b>;
		};

		ppmgr_reserved: linux,ppmgr {
			compatible = "shared-dma-pool";
			size = <0x00>;
			phandle = <0x41>;
		};

		codec_mm_cma: linux,codec_mm_cma {
			compatible = "shared-dma-pool";
			reusable;
			size = <0x10400000>;
			alignment = <0x400000>;
			linux,contiguous-region;
			phandle = <0x3e>;
		};

		picdec_cma_reserved: linux,picdec {
			compatible = "shared-dma-pool";
			reusable;
			size = <0x00>;
			alignment = <0x00>;
			linux,contiguous-region;
			phandle = <0x40>;
		};

		codec_mm_reserved: linux,codec_mm_reserved {
			compatible = "amlogic, codec-mm-reserved";
			size = <0x00>;
			alignment = <0x100000>;
			phandle = <0x3f>;
		};

		vdin1_cma_reserved: linux,vdin1_cma {
			compatible = "shared-dma-pool";
			reusable;
			size = <0x1000000>;
			alignment = <0x400000>;
			phandle = <0x43>;
		};
	};

	sysled {
		compatible = "amlogic, sysled";
		dev_name = "sysled";
		status = "disabled";
		led_gpio = <&gpio 76 GPIO_ACTIVE_HIGH>;
		led_active_low = <0x01>;
	};

	gpioleds {
		compatible = "gpio-leds";
		status = "okay";

		sys_red {
			label = "sys_red";
			gpios = <&gpio 76 GPIO_ACTIVE_HIGH>;
			default-state = "off";
		};

		sys_green {
			label = "sys_green";
			gpios = <&gpio 14 GPIO_ACTIVE_HIGH>;
			default-state = "on";
		};
	};

	gpio_keypad {
		compatible = "amlogic, gpio_keypad";
		status = "okay";
		scan_period = <20>;
		key_num = <1>;
		key_name = "f11";
		key_code = <0x45>;
		key-gpios = <&gpio_ao 2 GPIO_ACTIVE_LOW>;
		detect_mode = <0x00>;
	};

	vout {
		compatible = "amlogic, vout";
		dev_name = "vout";
		status = "okay";
		fr_auto_policy = <0x00>;
	};

	cvbsout {
		compatible = "amlogic, cvbsout-gxlx";
		dev_name = "cvbsout";
		status = "okay";
		clocks = <&clkc CLKID_VCLK2_ENCI>,
		         <&clkc CLKID_VCLK2_VENCI0>,
		         <&clkc CLKID_VCLK2_VENCI1>,
		         <&clkc CLKID_DAC_CLK>;
		clock-names = "venci_top_gate", "venci_0_gate", "venci_1_gate", "vdac_clk_gate";
		performance = <0x1bf0 0x09 0x1b56 0x343 0x1b12 0x8080 0x1b05 0xfd 0x1c59 0xf752 0xffff 0x00>;
	};

	meson-fb {
		compatible = "amlogic, meson-gxl";
		memory-region = <&logo_reserved>;
		dev_name = "meson-fb";
		status = "okay";
		interrupts = <GIC_SPI 3 IRQ_TYPE_EDGE_RISING>, <GIC_SPI 89 IRQ_TYPE_EDGE_RISING>;
		interrupt-names = "viu-vsync", "rdma";
		mem_size = <0x800000 0x1800000 0x100000>;
		display_mode_default = "720p60hz";
		scale_mode = <0x01>;
		display_size_default = <0x500 0x2d0 0x500 0x870 0x20>;
		logo_addr = "0x7f800000";
	};

	ge2d {
		compatible = "amlogic, ge2d-gxl";
		dev_name = "ge2d";
		status = "okay";
		interrupts = <GIC_SPI 150 IRQ_TYPE_EDGE_RISING>;
		interrupt-names = "ge2d";
		clocks = <&clkc CLKID_VAPB_MUX>, <&clkc CLKID_G2D>, <&clkc CLKID_GE2D_GATE>;
		clock-names = "clk_vapb_0", "clk_ge2d", "clk_ge2d_gate";
	};

	codec_io {
		compatible = "amlogic, codec_io";
		#address-cells = <1>;
		#size-cells = <1>;
		ranges;

		io_cbus_base {
			reg = <0xc1100000 0x100000>;
		};

		io_dos_base {
			reg = <0xc8820000 0x10000>;
		};

		io_hiubus_base {
			reg = <0xc883c000 0x2000>;
		};

		io_aobus_base {
			reg = <0xc8100000 0x100000>;
		};

		io_vcbus_base {
			reg = <0xd0100000 0x40000>;
		};

		io_dmc_base {
			reg = <0xc8838000 0x400>;
		};
	};

	codec_mm {
		compatible = "amlogic, codec, mm";
		memory-region = <&codec_mm_cma>, <&codec_mm_reserved>;
		dev_name = "codec_mm";
		status = "okay";
	};

	canvas {
		compatible = "amlogic, meson, canvas";
		dev_name = "amlogic-canvas";
		status = "ok";
		reg = <0xc8838000 0x400>;
	};

	mesonstream {
		compatible = "amlogic, codec, streambuf";
		dev_name = "mesonstream";
		status = "okay";
		clocks = <&clkc CLKID_DOS_PARSER>,
		         <&clkc CLKID_DEMUX>,
		         <&clkc CLKID_DOS>,
		         <&clkc CLKID_CLK81>,
		         <&clkc CLKID_VDEC_MUX>,
		         <&clkc CLKID_HCODEC_MUX>,
		         <&clkc CLKID_HEVC_MUX>;
		clock-names = "parser_top", "demux", "vdec", "clk_81", "clk_vdec_mux", "clk_hcodec_mux", "clk_hevc_mux";
	};

	vdec {
		compatible = "amlogic, vdec";
		dev_name = "vdec.0";
		status = "okay";
		interrupts = <GIC_SPI 3 IRQ_TYPE_EDGE_RISING>,
		             <GIC_SPI 23 IRQ_TYPE_EDGE_RISING>,
		             <GIC_SPI 32 IRQ_TYPE_EDGE_RISING>,
		             <GIC_SPI 43 IRQ_TYPE_EDGE_RISING>,
		             <GIC_SPI 44 IRQ_TYPE_EDGE_RISING>,
		             <GIC_SPI 45 IRQ_TYPE_EDGE_RISING>;
		interrupt-names = "vsync", "demux", "parser", "mailbox_0", "mailbox_1", "mailbox_2";
	};

	picdec {
		compatible = "amlogic, picdec";
		memory-region = <&picdec_cma_reserved>;
		dev_name = "picdec";
		status = "okay";
	};

	ppmgr {
		compatible = "amlogic, ppmgr";
		memory-region = <&ppmgr_reserved>;
		dev_name = "ppmgr";
		status = "okay";
	};

	deinterlace {
		compatible = "amlogic, deinterlace";
		status = "okay";
		flag_cma = <0x04>;
		memory-region = <&di_cma_reserved>;
		interrupts = <GIC_SPI 46 IRQ_TYPE_EDGE_RISING>, <GIC_SPI 6 IRQ_TYPE_EDGE_RISING>;
		interrupt-names = "de_irq", "timerc";
		buffer-size = <0x2fd000>;
		hw-version = <0x02>;
	};

	tunnel_sync {
		compatible = "amlogic, tunnel_sync";
		dev_name = "tunnel_sync";
		status = "okay";
		interrupts = <GIC_SPI 3 IRQ_TYPE_EDGE_RISING>;
		interrupt-names = "vsync";
	};

	ionvideo {
		compatible = "amlogic, ionvideo";
		dev_name = "ionvideo";
		status = "okay";
	};

	amlvideo {
		compatible = "amlogic, amlvideo";
		dev_name = "amlvideo";
		status = "okay";
	};

	meson_uvm {
		compatible = "amlogic, meson_uvm";
		status = "okay";
	};

	meson_videotunnel {
		compatible = "amlogic, meson_videotunnel";
		status = "okay";
	};

	video_composer {
		compatible = "amlogic, video_composer";
		dev_name = "video_composer";
		status = "okay";
	};

	dvb {
		compatible = "amlogic, dvb";
		dev_name = "dvb";
		status = "disabled";
		ts2 = "parallel";
		ts2_control = <0x00>;
		ts2_invert = <0x00>;
		interrupts = <GIC_SPI 23 IRQ_TYPE_EDGE_RISING>,
		             <GIC_SPI 5 IRQ_TYPE_EDGE_RISING>,
		             <GIC_SPI 53 IRQ_TYPE_EDGE_RISING>,
		             <GIC_SPI 19 IRQ_TYPE_EDGE_RISING>,
		             <GIC_SPI 25 IRQ_TYPE_EDGE_RISING>,
		             <GIC_SPI 18 IRQ_TYPE_EDGE_RISING>,
		             <GIC_SPI 24 IRQ_TYPE_EDGE_RISING>;
		interrupt-names = "demux0_irq", "demux1_irq", "demux2_irq", "dvr0_irq", "dvr1_irq", "dvrfill0_fill", "dvrfill1_flush";
		clocks = <&clkc CLKID_DEMUX>,
		         <&clkc CLKID_ASYNC_FIFO>,
		         <&clkc CLKID_AHB_ARB0>,
		         <&clkc CLKID_DOS_PARSER>;
		clock-names = "demux", "asyncfifo", "ahbarb0", "uparsertop";
	};

	vdin0 {
		compatible = "amlogic, vdin";
		dev_name = "vdin0";
		status = "disabled";
		reserve-iomap = "true";
		flag_cma = <0x01>;
		cma_size = <0x18>;
		interrupts = <GIC_SPI 83 IRQ_TYPE_EDGE_RISING>;
		rdma-irq = <0x02>;
		vdin_id = <0x00>;
		tv_bit_mode = <0x15>;
	};

	vdin1 {
		compatible = "amlogic, vdin";
		memory-region = <&vdin1_cma_reserved>;
		dev_name = "vdin1";
		status = "disabled";
		reserve-iomap = "true";
		flag_cma = <0x00>;
		interrupts = <GIC_SPI 85 IRQ_TYPE_EDGE_RISING>;
		rdma-irq = <0x04>;
		vdin_id = <0x01>;
		tv_bit_mode = <0x01>;
	};

	amlvecm {
		compatible = "amlogic, vecm";
		dev_name = "aml_vecm";
		status = "okay";
		gamma_en = <0x00>;
		wb_en = <0x00>;
		cm_en = <0x00>;
		wb_sel = <0x00>;
		cfg_en_osd_100 = <0x03>;
		tx_op_color_primary = <0x00>;
	};

	amvenc_avc {
		compatible = "amlogic, amvenc_avc";
		dev_name = "amvenc_avc";
		status = "okay";
		interrupts = <GIC_SPI 45 IRQ_TYPE_EDGE_RISING>;
		interrupt-names = "mailbox_2";
	};

	hevc_enc {
		compatible = "cnm, HevcEnc";
		dev_name = "HevcEnc";
		status = "okay";
		interrupts = <GIC_SPI 187 IRQ_TYPE_EDGE_RISING>;
		interrupt-names = "wave420l_irq";
		#address-cells = <1>;
		#size-cells = <1>;
		ranges;

		io_reg_base {
			reg = <0xc8810000 0x4000>;
		};
	};

	vpu {
		compatible = "amlogic, vpu-gxl";
		dev_name = "vpu";
		status = "okay";
		clocks = <&clkc CLKID_VAPB_MUX>,
		         <&clkc CLKID_VPU_INTR>,
		         <&clkc CLKID_GP0_PLL>,
		         <&clkc CLKID_VPU_P0_COMP>,
		         <&clkc CLKID_VPU_P1_COMP>,
		         <&clkc CLKID_VPU_MUX>;
		clock-names = "vapb_clk", "vpu_intr_gate", "gp_pll", "vpu_clk0", "vpu_clk1", "vpu_clk";
		clk_level = <0x07>;
	};

	rdma {
		compatible = "amlogic, meson, rdma";
		dev_name = "amlogic-rdma";
		status = "ok";
		interrupts = <GIC_SPI 89 IRQ_TYPE_EDGE_RISING>;
		interrupt-names = "rdma";
	};

	rtc {
		compatible = "amlogic, aml_vrtc";
		alarm_reg_addr = <0xc81000a8>;
		timer_e_addr = <0xc1109988>;
		init_date = "2020/01/01";
		status = "okay";
	};

	bt-dev {
		compatible = "amlogic, bt-dev";
		dev_name = "bt-dev";
		status = "okay";
		gpio_en = <&gpio 99 GPIO_ACTIVE_HIGH>;
		gpio_reset = <&gpio 99 GPIO_ACTIVE_HIGH>;
	};

	wifi {
		compatible = "amlogic, aml_wifi";
		dev_name = "aml_wifi";
		status = "okay";
		interrupt_pin = <&gpio 100 GPIO_ACTIVE_HIGH>;
		interrupts = <GIC_SPI 68 IRQ_TYPE_LEVEL_HIGH>;
		irq_trigger_type = "GPIO_IRQ_HIGH";
		power_on_pin = <&gpio 88 GPIO_ACTIVE_HIGH>;
		dhd_static_buf;
		pinctrl-names = "wifi_32k_pins";
		pinctrl-0 = <&wifi_32k_pins>;
	};

	wifi_pwm_conf: wifi_pwm_conf {
		phandle = <0xc7>;

		pwm_channel1_conf {
			pwms = <&pwm_ef 0 30541 0>;
			duty-cycle = <15270>;
			times = <8>;
		};

		pwm_channel2_conf {
			pwms = <&pwm_ef 2 30500 0>;
			duty-cycle = <15250>;
			times = <12>;
		};
	};

	sd_emmc_c: emmc@d0074000 {
		status = "okay";
		compatible = "amlogic, meson-mmc-gxlx";
		reg = <0xd0074000 0x2000>;
		interrupts = <GIC_SPI 218 IRQ_TYPE_EDGE_RISING>;
		pinctrl-names = "emmc_clk_cmd_pins", "emmc_all_pins";
		pinctrl-0 = <&emmc_clk_cmd_pins>;
		pinctrl-1 = <&emmc_conf_pull_up>, <&emmc_conf_pull_done>;
		clocks = <&clkc CLKID_SD_EMMC_C>,
		         <&clkc CLKID_SD_EMMC_C_P0_COMP>,
		         <&clkc CLKID_FCLK_DIV2>;
		clock-names = "core", "clkin0", "clkin1";
		bus-width = <8>;
		cap-sd-highspeed;
		cap-mmc-highspeed;
		max-frequency = <200000000>;
		non-removable;
		disable-wp;
		phandle = <0xc8>;

		emmc {
			pinname = "emmc";
			ocr_avail = <0x200080>;
			caps = "MMC_CAP_8_BIT_DATA", "MMC_CAP_MMC_HIGHSPEED", "MMC_CAP_SD_HIGHSPEED", "MMC_CAP_NONREMOVABLE", "MMC_CAP_HW_RESET", "MMC_CAP_ERASE", "MMC_CAP_CMD23";
			f_min = <400000>;
			f_max = <50000000>;
			max_req_size = <0x20000>;
			gpio_dat3 = <&gpio 32 GPIO_ACTIVE_HIGH>;
			hw_reset = <&gpio 38 GPIO_ACTIVE_HIGH>;
			card_type = <0x01>;
		};
	};

	sd_emmc_b: sd@d0072000 {
		status = "okay";
		compatible = "amlogic, meson-mmc-gxlx";
		reg = <0xd0072000 0x2000>;
		interrupts = <GIC_SPI 217 IRQ_TYPE_EDGE_RISING>;
		pinctrl-names = "sd_all_pins", "sd_clk_cmd_pins", "sd_1bit_pins", "sd_clk_cmd_uart_pins", "sd_1bit_uart_pins", "sd_to_ao_uart_pins", "ao_to_sd_uart_pins", "ao_to_sd_jtag_pins", "sd_to_ao_jtag_pins";
		pinctrl-0 = <&sd_all_pins>;
		pinctrl-1 = <&sd_clk_cmd_pins>;
		pinctrl-2 = <&sd_1bit_pins>;
		pinctrl-3 = <&sd_to_ao_uart_clr_pins>, <&sd_clk_cmd_pins>, <&ao_to_sd_uart_pins>;
		pinctrl-4 = <&sd_to_ao_uart_clr_pins>, <&sd_1bit_pins>, <&ao_to_sd_uart_pins>;
		pinctrl-5 = <&sd_all_pins>, <&sd_to_ao_uart_pins>;
		pinctrl-6 = <&sd_to_ao_uart_clr_pins>, <&ao_to_sd_uart_pins>;
		pinctrl-7 = <&sd_to_ao_uart_clr_pins>, <&ao_to_sd_uart_pins>;
		pinctrl-8 = <&sd_all_pins>, <&sd_to_ao_uart_pins>;
		clocks = <&clkc CLKID_SD_EMMC_B>,
		         <&clkc CLKID_SD_EMMC_B_P0_COMP>,
		         <&clkc CLKID_FCLK_DIV2>;
		clock-names = "core", "clkin0", "clkin1";
		bus-width = <4>;
		cap-sd-highspeed;
		max-frequency = <100000000>;
		disable-wp;
		phandle = <0xc9>;

		sd {
			pinname = "sd";
			ocr_avail = <0x200080>;
			caps = "MMC_CAP_4_BIT_DATA", "MMC_CAP_MMC_HIGHSPEED", "MMC_CAP_SD_HIGHSPEED";
			f_min = <400000>;
			f_max = <100000000>;
			max_req_size = <0x20000>;
			gpio_dat3 = <&gpio 49 GPIO_ACTIVE_HIGH>;
			jtag_pin = <&gpio 45 GPIO_ACTIVE_HIGH>;
			gpio_cd = <&gpio 51 GPIO_ACTIVE_HIGH>;
			card_type = <0x05>;
		};
	};

	sd_emmc_a: sdio@d0070000 {
		status = "okay";
		compatible = "amlogic, meson-mmc-gxlx";
		reg = <0xd0070000 0x2000>;
		interrupts = <GIC_SPI 216 IRQ_TYPE_LEVEL_HIGH>;
		pinctrl-names = "sdio_clk_cmd_pins", "sdio_all_pins";
		pinctrl-0 = <&sdio_clk_cmd_pins>;
		pinctrl-1 = <&sdio_all_pins>;
		clocks = <&clkc CLKID_SD_EMMC_A>,
		         <&clkc CLKID_SD_EMMC_A_P0_COMP>,
		         <&clkc CLKID_FCLK_DIV2>;
		clock-names = "core", "clkin0", "clkin1";
		bus-width = <4>;
		cap-sd-highspeed;
		cap-mmc-highspeed;
		max-frequency = <100000000>;
		non-removable;
		disable-wp;
		phandle = <0xca>;

		sdio {
			pinname = "sdio";
			ocr_avail = <0x200080>;
			caps = "MMC_CAP_4_BIT_DATA", "MMC_CAP_MMC_HIGHSPEED", "MMC_CAP_SD_HIGHSPEED", "MMC_CAP_NONREMOVABLE", "MMC_CAP_UHS_SDR12", "MMC_CAP_UHS_SDR25", "MMC_CAP_UHS_SDR50", "MMC_PM_KEEP_POWER", "MMC_CAP_SDIO_IRQ";
			f_min = <400000>;
			f_max = <50000000>;
			max_req_size = <0x20000>;
			card_type = <0x03>;
			auto_clk_close = <0x01>;
		};
	};

	mtd_nand {
		compatible = "amlogic, aml_mtd_nand";
		dev_name = "mtdnand";
		status = "disabled";
		reg = <0xd0074800 0x200>;
		interrupts = <GIC_SPI 34 IRQ_TYPE_EDGE_RISING>;
		pinctrl-names = "nand_rb_mod", "nand_norb_mod", "nand_cs_only";
		pinctrl-0 = <&all_nand_pins>;
		pinctrl-1 = <&all_nand_pins>;
		pinctrl-2 = <&nand_cs_pins>;
		device_id = <0x00>;
		plat-names = "bootloader", "nandnormal";
		plat-num = <2>;
		plat-part-0 = <&bootloader>;
		plat-part-1 = <&nandnormal>;

		bootloader: bootloader {
			enable_pad = "ce0";
			busy_pad = "rb0";
			timming_mode = "mode5";
			bch_mode = "bch60_1k";
			t_rea = <0x14>;
			t_rhoh = <0x0f>;
			chip_num = <1>;
			part_num = <0>;
			rb_detect = <0x01>;
			phandle = <0x53>;
		};

		nandnormal: nandnormal {
			enable_pad = "ce0", "ce1";
			busy_pad = "rb0", "rb1";
			timming_mode = "mode5";
			bch_mode = "bch60_1k";
			plane_mode = "twoplane";
			t_rea = <0x14>;
			t_rhoh = <0x0f>;
			chip_num = <2>;
			part_num = <3>;
			partition = <&nand_partitions>;
			rb_detect = <0x01>;
			phandle = <0x54>;
		};

		nand_partitions: nand_partition {
			phandle = <0x55>;

			logo {
				offset = <0x00 0x00>;
				size = <0x00 0x200000>;
			};

			recovery {
				offset = <0x00 0x00>;
				size = <0x00 0x1000000>;
			};

			boot {
				offset = <0x00 0x00>;
				size = <0x00 0xc00000>;
			};

			system {
				offset = <0x00 0x00>;
				size = <0x00 0xdc40000>;
			};

			data {
				offset = <0xffffffff 0xffffffff>;
				size = <0x00 0x00>;
			};
		};
	};

	ethmac: ethernet@0xc9410000 {
		compatible = "amlogic, gxbb-eth-dwmac";
		reg = <0xc9410000 0x10000 0xc8834540 0x08 0xc8834558 0x0c 0xc1104408 0x04>;
		interrupts = <GIC_SPI 8 IRQ_TYPE_EDGE_RISING>;
		pinctrl-names = "external_eth_pins";
		pinctrl-0 = <&external_eth_pins>;
		rst_pin-gpios = <&gpio 14 GPIO_ACTIVE_HIGH>;
		GPIOZ4_pin-gpios = <&gpio 4 GPIO_ACTIVE_HIGH>;
		GPIOZ5_pin-gpios = <&gpio 5 GPIO_ACTIVE_HIGH>;
		mc_val_internal_phy = <0x1800>;
		mc_val_external_phy = <0x1621>;
		cali_val = <0x20000>;
		interrupt-names = "macirq";
		clocks = <&clkc CLKID_ETH>;
		clock-names = "ethclk81";
		internal_phy = <0x01>;
		phandle = <0xcb>;
	};

	dwc3: dwc3@c9000000 {
		compatible = "synopsys, dwc3";
		reg = <0xc9000000 0x100000>;
		interrupts = <GIC_SPI 30 IRQ_TYPE_LEVEL_HIGH>;
		usb-phy = <0x57 0x58>;
		cpu-type = "gxl";
		clock-src = "usb3.0";
		phandle = <0xcc>;
	};

	usb2_phy: usb2phy@d0078000 {
		compatible = "amlogic, amlogic-new-usb2";
		portnum = <0x03>;
		reg = <0xd0078000 0x80 0xc1104408 0x04>;
		phandle = <0x57>;
	};

	usb3_phy: usb3phy@d0078080 {
		compatible = "amlogic, amlogic-new-usb3";
		portnum = <0x00>;
		reg = <0xd0078080 0x20>;
		phandle = <0x58>;
	};

	dwc2_a {
		compatible = "amlogic, dwc2";
		device_name = "dwc2_a";
		reg = <0xc9100000 0x40000>;
		status = "okay";
		interrupts = <GIC_SPI 31 IRQ_TYPE_LEVEL_HIGH>;
		pl-periph-id = <0x00>;
		clock-src = "usb0";
		port-id = <0x00>;
		port-type = <0x02>;
		port-speed = <0x00>;
		port-config = <0x00>;
		port-dma = <0x00>;
		port-id-mode = <0x00>;
		usb-fifo = <0x2d8>;
		cpu-type = "gxl";
		controller-type = <0x01>;
		phy-reg = <0xd0078000>;
		phy-reg-size = <0xa0>;
		clocks = <&clkc CLKID_USB_GENERAL>, <&clkc CLKID_USB1_TO_DDR>, <&clkc CLKID_USB1>;
		clock-names = "usb_general", "usb1", "usb1_to_ddr";
	};

	unifykey {
		compatible = "amlogic, unifykey";
		status = "ok";
		unifykey-num = <19>;
		unifykey-index-0 = <0x59>;
		unifykey-index-1 = <0x5a>;
		unifykey-index-2 = <0x5b>;
		unifykey-index-3 = <0x5c>;
		unifykey-index-4 = <0x5d>;
		unifykey-index-5 = <0x5e>;
		unifykey-index-6 = <0x5f>;
		unifykey-index-7 = <0x60>;
		unifykey-index-8 = <0x61>;
		unifykey-index-9 = <0x62>;
		unifykey-index-10 = <0x63>;
		unifykey-index-11 = <0x64>;
		unifykey-index-12 = <0x65>;
		unifykey-index-13 = <0x66>;
		unifykey-index-14 = <0x67>;
		unifykey-index-15 = <0x68>;
		unifykey-index-16 = <0x69>;
		unifykey-index-17 = <0x6a>;
		unifykey-index-18 = <0x6b>;

		keysn_0: key_0 {
			key-name = "usid";
			key-device = "normal";
			key-permit = "read", "write", "del";
			phandle = <0x59>;
		};

		keysn_1: key_1 {
			key-name = "mac";
			key-device = "normal";
			key-permit = "read", "write", "del";
			phandle = <0x5a>;
		};

		keysn_2: key_2 {
			key-name = "hdcp";
			key-device = "secure";
			key-type = "sha1";
			key-permit = "read", "write", "del";
			phandle = <0x5b>;
		};

		keysn_3: key_3 {
			key-name = "secure_boot_set";
			key-device = "efuse";
			key-permit = "write";
			phandle = <0x5c>;
		};

		keysn_4: key_4 {
			key-name = "mac_bt";
			key-device = "normal";
			key-permit = "read", "write", "del";
			key-type = "mac";
			phandle = <0x5d>;
		};

		keysn_5: key_5 {
			key-name = "mac_wifi";
			key-device = "normal";
			key-permit = "read", "write", "del";
			key-type = "mac";
			phandle = <0x5e>;
		};

		keysn_6: key_6 {
			key-name = "hdcp2_tx";
			key-device = "normal";
			key-permit = "read", "write", "del";
			phandle = <0x5f>;
		};

		keysn_7: key_7 {
			key-name = "hdcp2_rx";
			key-device = "normal";
			key-permit = "read", "write", "del";
			phandle = <0x60>;
		};

		keysn_8: key_8 {
			key-name = "widevinekeybox";
			key-device = "secure";
			key-permit = "read", "write", "del";
			phandle = <0x61>;
		};

		keysn_9: key_9 {
			key-name = "deviceid";
			key-device = "normal";
			key-permit = "read", "write", "del";
			phandle = <0x62>;
		};

		keysn_10: key_10 {
			key-name = "hdcp22_fw_private";
			key-device = "secure";
			key-permit = "read", "write", "del";
			phandle = <0x63>;
		};

		keysn_11: key_11 {
			key-name = "PlayReadykeybox25";
			key-device = "secure";
			key-permit = "read", "write", "del";
			phandle = <0x64>;
		};

		keysn_12: key_12 {
			key-name = "prpubkeybox";
			key-device = "secure";
			key-permit = "read", "write", "del";
			phandle = <0x65>;
		};

		keysn_13: key_13 {
			key-name = "prprivkeybox";
			key-device = "secure";
			key-permit = "read", "write", "del";
			phandle = <0x66>;
		};

		keysn_14: key_14 {
			key-name = "attestationkeybox";
			key-device = "secure";
			key-permit = "read", "write", "del";
			phandle = <0x67>;
		};

		keysn_15: key_15 {
			key-name = "region_code";
			key-device = "normal";
			key-permit = "read", "write", "del";
			phandle = <0x68>;
		};

		keysn_16: key_16 {
			key-name = "netflix_mgkid";
			key-device = "secure";
			key-permit = "read", "write", "del";
			phandle = <0x69>;
		};

		keysn_17: key_17 {
			key-name = "attestationdevidbox";
			key-device = "secure";
			key-permit = "read", "write", "del";
			phandle = <0x6a>;
		};

		keysn_18: key_18 {
			key-name = "oemkey";
			key-device = "normal";
			key-permit = "read", "write", "del";
			phandle = <0x6b>;
		};
	};

	amhdmitx: amhdmitx {
		compatible = "amlogic, amhdmitx";
		dev_name = "amhdmitx";
		status = "okay";
		vend-data = <&vend_data>;
		pinctrl-names = "hdmitx_hpd", "hdmitx_ddc";
		pinctrl-0 = <&hdmitx_hpd>;
		pinctrl-1 = <&hdmitx_ddc>;
		interrupts = <GIC_SPI 57 IRQ_TYPE_EDGE_RISING>;
		interrupt-names = "hdmitx_hpd";
		ic_type = <0x10>;
		phandle = <0xcd>;

		vend_data: vend_data {
			vendor_name = "Amlogic";
			vendor_id = <0x00>;
			product_desc = "MBox Meson Ref";
			phandle = <0x6c>;
		};
	};

	aocec: aocec {
		compatible = "amlogic, amlogic-aocec";
		device_name = "aocec";
		status = "okay";
		vendor_id = <0x00>;
		cec_osd_string = "MBox";
		cec_version = <5>;
		port_num = <1>;
		arc_port_mask = <0x00>;
		interrupts = <GIC_SPI 199 IRQ_TYPE_EDGE_RISING>;
		interrupt-names = "hdmi_aocec";
		pinctrl-names = "default";
		pinctrl-0 = <&hdmitx_aocec>;
		reg = <0xc810023c 0x04>, <0xc8100000 0x200>;
		reg-names = "ao_exit", "ao";
		phandle = <0xce>;
	};

	i2s_dai: I2S {
		#sound-dai-cells = <0>;
		compatible = "amlogic, aml-i2s-dai";
		clocks = <&clkc CLKID_MPLL2>,
		         <&clkc CLKID_AMCLK_COMP>,
		         <&clkc CLKID_AIU_GLUE>,
		         <&clkc CLKID_IEC958>,
		         <&clkc CLKID_I2S_OUT>,
		         <&clkc CLKID_AMCLK>,
		         <&clkc CLKID_AIFIFO2>,
		         <&clkc CLKID_MIXER>,
		         <&clkc CLKID_MIXER_IFACE>,
		         <&clkc CLKID_ADC>,
		         <&clkc CLKID_AIU_TOP>,
		         <&clkc CLKID_AOCLK_GATE>,
		         <&clkc CLKID_I2S_SPDIF>;
		clock-names = "mpll", "mclk", "top_glue", "aud_buf", "i2s_out", "amclk_measure", "aififo2", "aud_mixer", "mixer_reg", "adc", "top_level", "aoclk", "aud_in";
		i2s_pos_sync = <0x00>;
		phandle = <0x7b>;
	};

	dmic: snd_dmic {
		#sound-dai-cells = <0>;
		compatible = "aml, aml_snd_dmic";
		reg = <0xd0042000 0x2000>;
		status = "disabled";
		resets = <&clkc 212>;
		reset-names = "pdm";
		pinctrl-names = "audio_dmic";
		pinctrl-0 = <&aml_dmic_pins>;
		clocks = <&clkc CLKID_PDM_COMP>, <&clkc CLKID_AMCLK_COMP>;
		clock-names = "pdm", "mclk";
		phandle = <0xcf>;
	};

	spdif_dai: SPDIF {
		#sound-dai-cells = <0>;
		compatible = "amlogic, aml-spdif-dai";
		clocks = <&clkc CLKID_MPLL1>,
		         <&clkc CLKID_I958_COMP>,
		         <&clkc CLKID_AMCLK_COMP>,
		         <&clkc CLKID_I958_COMP_SPDIF>,
		         <&clkc CLKID_CLK81>,
		         <&clkc CLKID_IEC958>,
		         <&clkc CLKID_IEC958_GATE>;
		clock-names = "mpll1", "i958", "mclk", "spdif", "clk_81", "iec958", "iec958_amclk";
		phandle = <0x7c>;
	};

	pcm_dai: PCM {
		#sound-dai-cells = <0>;
		compatible = "amlogic, aml-pcm-dai";
		pinctrl-names = "audio_pcm";
		clocks = <&clkc CLKID_MPLL0>,
		         <&clkc CLKID_PCM_MCLK_COMP>,
		         <&clkc CLKID_PCM_SCLK_GATE>;
		clock-names = "mpll0", "pcm_mclk", "pcm_sclk";
		pcm_mode = <0x01>;
		dai-format = "dsp_a";
		dai-tdm-slot-tx-mask = <0x01>;
		dai-tdm-slot-rx-mask = <0x01>;
		dai-tdm-slot-num = <2>;
		dai-tdm-slot-width = <16>;
		phandle = <0x7d>;
	};

	i2s_plat: i2s_platform {
		compatible = "amlogic, aml-i2s";
		interrupts = <GIC_SPI 29 IRQ_TYPE_EDGE_RISING>;
		phandle = <0x79>;
	};

	pcm_plat: pcm_platform {
		compatible = "amlogic, aml-pcm";
		phandle = <0x7a>;
	};

	spdif_codec: spdif_codec {
		#sound-dai-cells = <0>;
		compatible = "amlogic, aml-spdif-codec";
		pinctrl-names = "audio_spdif_out";
		pinctrl-0 = <&audio_spdif_pins>;
		phandle = <0x7f>;
	};

	pcm_codec: pcm_codec {
		#sound-dai-cells = <0>;
		compatible = "amlogic, pcm2BT-codec";
		phandle = <0x80>;
	};

	dummy_codec: dummy {
		#sound-dai-cells = <0>;
		compatible = "amlogic, aml_dummy_codec";
		status = "disable";
		phandle = <0xd0>;
	};

	amlogic_codec: t9015 {
		#sound-dai-cells = <0>;
		compatible = "amlogic, aml_codec_T9015";
		reg = <0xc8832000 0x14>;
		status = "okay";
		phandle = <0x7e>;
	};

	aml_sound_meson {
		compatible = "aml, meson-snd-card";
		status = "okay";
		aml-sound-card,format = "i2s";
		aml_sound_card,name = "AML-MESONAUDIO";
		aml,audio-routing = "Ext Spk", "LOUTL", "Ext Spk", "LOUTR";
		mute_gpio-gpios = <&gpio 21 GPIO_ACTIVE_HIGH>;
		mute_inv;
		hp_disable;
		hp_paraments = <0x320 0x12c 0x00 0x05 0x01>;
		pinctrl-names = "audio_i2s";
		pinctrl-0 = <&audio_i2s_pins>;
		cpu_list = <&cpudai0>, <&cpudai1>, <&cpudai2>;
		codec_list = <&codec0>, <&codec1>, <&codec2>;
		plat_list = <&i2s_plat>, <&i2s_plat>, <&pcm_plat>;

		cpudai0: cpudai0 {
			sound-dai = <&i2s_dai>;
			phandle = <0x73>;
		};

		cpudai1: cpudai1 {
			sound-dai = <&spdif_dai>;
			phandle = <0x74>;
		};

		cpudai2: cpudai2 {
			sound-dai = <&pcm_dai>;
			phandle = <0x75>;
		};

		codec0: codec0 {
			sound-dai = <&amlogic_codec>;
			phandle = <0x76>;
		};

		codec1: codec1 {
			sound-dai = <&spdif_codec>;
			phandle = <0x77>;
		};

		codec2: codec2 {
			sound-dai = <&pcm_codec>;
			phandle = <0x78>;
		};
	};

	aml_sensor0: aml-sensor@0 {
		compatible = "amlogic, aml-thermal";
		device_name = "thermal";
		status = "okay";
		#thermal-sensor-cells = <1>;
		phandle = <0x81>;

		cooling_devices {

			cpufreq_cool_cluster0 {
				min_state = <1000000>;
				dyn_coeff = <140>;
				cluster_id = <0>;
				node_name = "cpufreq_cool0";
				device_type = "cpufreq";
			};

			cpucore_cool_cluster0 {
				min_state = <2>;
				dyn_coeff = <0>;
				cluster_id = <0>;
				node_name = "cpucore_cool0";
				device_type = "cpucore";
			};

			gpufreq_cool {
				min_state = <400>;
				dyn_coeff = <437>;
				cluster_id = <0>;
				node_name = "mali";
				device_type = "gpufreq";
			};

			gpucore_cool {
				min_state = <1>;
				dyn_coeff = <0>;
				cluster_id = <0>;
				node_name = "gpucore_cool0";
				device_type = "gpucore";
			};
		};

		cpufreq_cool0: cpufreq_cool0 {
			#cooling-cells = <2>;
			phandle = <0x83>;
		};

		cpucore_cool0: cpucore_cool0 {
			#cooling-cells = <2>;
			phandle = <0x84>;
		};

		gpucore_cool0: gpucore_cool0 {
			#cooling-cells = <2>;
			phandle = <0x86>;
		};
	};

	thermal-zones {

		soc_thermal {
			polling-delay = <1000>;
			polling-delay-passive = <100>;
			sustainable-power = <2150>;
			thermal-sensors = <&aml_sensor0 3>;

			trips {

				switch_on: trip-point@0 {
					temperature = <75000>;
					hysteresis = <1000>;
					type = "passive";
					phandle = <0xd1>;
				};

				control: trip-point@1 {
					temperature = <85000>;
					hysteresis = <1000>;
					type = "passive";
					phandle = <0x82>;
				};

				hot: trip-point@2 {
					temperature = <95000>;
					hysteresis = <5000>;
					type = "hot";
					phandle = <0xd2>;
				};

				critical: trip-point@3 {
					temperature = <260000>;
					hysteresis = <1000>;
					type = "critical";
					phandle = <0xd3>;
				};
			};

			cooling-maps {

				cpufreq_cooling_map {
					trip = <&control>;
					cooling-device = <&cpufreq_cool0 0 4>;
					contribution = <1024>;
				};

				cpucore_cooling_map {
					trip = <&control>;
					cooling-device = <&cpucore_cool0 0 3>;
					contribution = <1024>;
				};

				gpufreq_cooling_map {
					trip = <&control>;
					cooling-device = <&gpu 0 4>;
					contribution = <1024>;
				};

				gpucore_cooling_map {
					trip = <&control>;
					cooling-device = <&gpucore_cool0 0 2>;
					contribution = <1024>;
				};
			};
		};
	};
};
